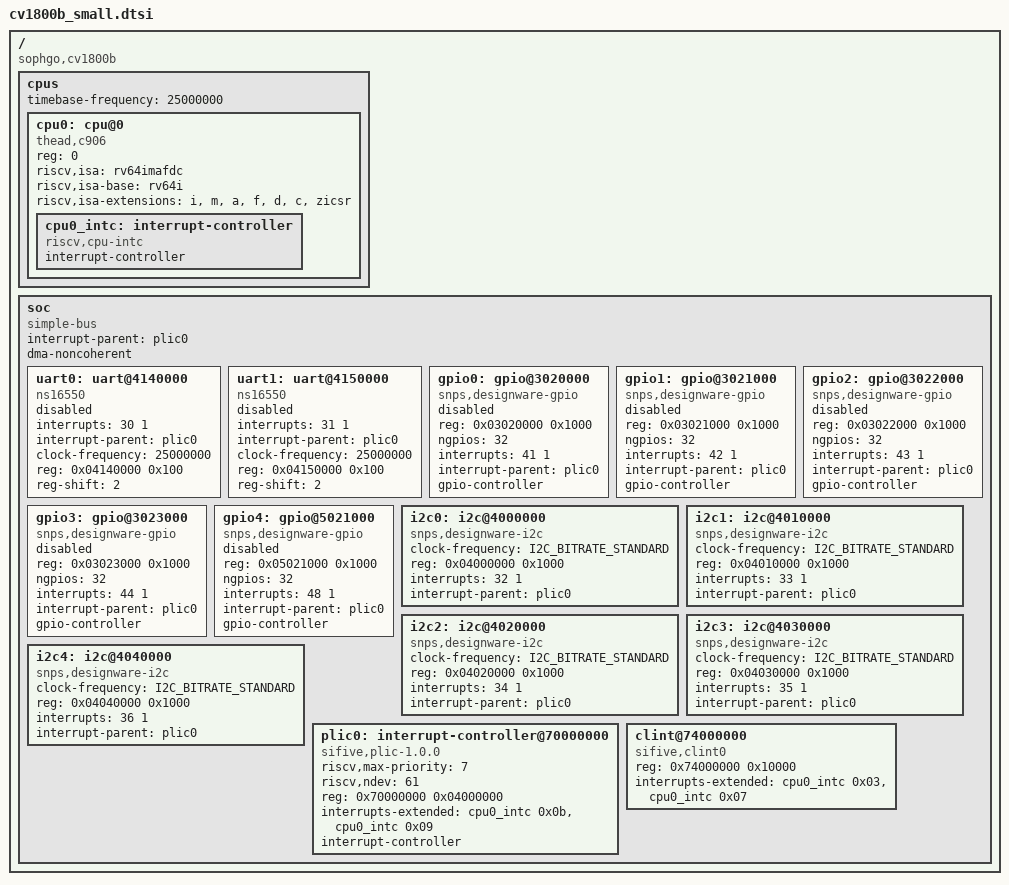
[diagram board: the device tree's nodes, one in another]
// SPDX-License-Identifier: (GPL-2.0 OR MIT)
/*
 * Copyright (C) 2024 Junhui Liu <liujh2818@outlook.com>
 */

#include <zephyr/dt-bindings/i2c/i2c.h>

/ {
	compatible = "sophgo,cv1800b";
	#address-cells = <1>;
	#size-cells = <1>;

	cpus: cpus {
		#address-cells = <1>;
		#size-cells = <0>;
		timebase-frequency = <25000000>;

		cpu0: cpu@0 {
			compatible = "thead,c906", "riscv";
			device_type = "cpu";
			reg = <0>;
			riscv,isa = "rv64imafdc";
			riscv,isa-base = "rv64i";
			riscv,isa-extensions = "i", "m", "a", "f", "d", "c", "zicsr";

			cpu0_intc: interrupt-controller {
				compatible = "riscv,cpu-intc";
				interrupt-controller;
				#interrupt-cells = <1>;
			};
		};
	};

	soc {
		compatible = "simple-bus";
		interrupt-parent = <&plic0>;
		#address-cells = <1>;
		#size-cells = <1>;
		dma-noncoherent;
		ranges;

		uart0: uart@4140000 {
			interrupts = < 30 1 >;
			interrupt-parent = < &plic0 >;
			clock-frequency = < 25000000 >;
			reg = < 0x04140000 0x100 >;
			compatible = "ns16550";
			reg-shift = < 2 >;
			status = "disabled";
		};

		uart1: uart@4150000 {
			interrupts = < 31 1 >;
			interrupt-parent = < &plic0 >;
			clock-frequency = < 25000000 >;
			reg = < 0x04150000 0x100 >;
			compatible = "ns16550";
			reg-shift = < 2 >;
			status = "disabled";
		};

		gpio0: gpio@3020000 {						/* porta */
			#address-cells = <1>;
			#size-cells = <0>;
			compatible = "snps,designware-gpio";
			reg = <0x03020000 0x1000>;
			ngpios = <32>;
			interrupts = < 41 1 >;
			interrupt-parent = < &plic0 >;

			gpio-controller;
			#gpio-cells = <2>;
			status = "disabled";
		};

		gpio1: gpio@3021000 {						/* portb */
			compatible = "snps,designware-gpio";
			reg = <0x03021000 0x1000>;
			ngpios = <32>;
			interrupts = < 42 1 >;
			interrupt-parent = < &plic0 >;

			gpio-controller;
			#gpio-cells = <2>;
			status = "disabled";
		};

		gpio2: gpio@3022000 {						/* portc */
			compatible = "snps,designware-gpio";
			reg = <0x03022000 0x1000>;
			ngpios = <32>;
			interrupts = < 43 1 >;
			interrupt-parent = < &plic0 >;

			gpio-controller;
			#gpio-cells = <2>;
			status = "disabled";
		};

		gpio3: gpio@3023000 {						/* portd */
			compatible = "snps,designware-gpio";
			reg = <0x03023000 0x1000>;
			ngpios = <32>;
			interrupts = < 44 1 >;
			interrupt-parent = < &plic0 >;

			gpio-controller;
			#gpio-cells = <2>;
			status = "disabled";
		};

		gpio4: gpio@5021000 {						/* porte */
			compatible = "snps,designware-gpio";
			reg = <0x05021000 0x1000>;
			ngpios = <32>;
			interrupts = < 48 1 >;
			interrupt-parent = < &plic0 >;

			gpio-controller;
			#gpio-cells = <2>;
			status = "disabled";
		};

		i2c0: i2c@4000000 {
			compatible = "snps,designware-i2c";
			clock-frequency = <I2C_BITRATE_STANDARD>;
			#address-cells = <1>;
			#size-cells = <0>;
			reg = <0x04000000 0x1000>;
			interrupts = <32 1>;
			interrupt-parent = <&plic0>;

			status = "okay";
		};
	
		i2c1: i2c@4010000 {
			compatible = "snps,designware-i2c";
			clock-frequency = <I2C_BITRATE_STANDARD>;
			#address-cells = <1>;
			#size-cells = <0>;
			reg = <0x04010000 0x1000>;
			interrupts = <33 1>;
			interrupt-parent = <&plic0>;

			status = "okay";
		};

		i2c2: i2c@4020000 {
			compatible = "snps,designware-i2c";
			clock-frequency = <I2C_BITRATE_STANDARD>;
			#address-cells = <1>;
			#size-cells = <0>;
			reg = <0x04020000 0x1000>;
			interrupts = <34 1>;
			interrupt-parent = <&plic0>;

			status = "okay";
		};

		i2c3: i2c@4030000 {
			compatible = "snps,designware-i2c";
			clock-frequency = <I2C_BITRATE_STANDARD>;
			#address-cells = <1>;
			#size-cells = <0>;
			reg = <0x04030000 0x1000>;
			interrupts = <35 1>;
			interrupt-parent = <&plic0>;

			status = "okay";
		};

		i2c4: i2c@4040000 {
			compatible = "snps,designware-i2c";
			clock-frequency = <I2C_BITRATE_STANDARD>;
			#address-cells = <1>;
			#size-cells = <0>;
			reg = <0x04040000 0x1000>;
			interrupts = <36 1>;
			interrupt-parent = <&plic0>;

			status = "okay";
		};

		plic0: interrupt-controller@70000000 {
			riscv,max-priority = <7>;
			riscv,ndev = < 61 >;
			reg = <0x70000000 0x04000000>;
			interrupts-extended = <&cpu0_intc 0x0b &cpu0_intc 0x09>;
			interrupt-controller;
			compatible = "sifive,plic-1.0.0";
			#address-cells = < 0x00 >;
			#interrupt-cells = < 0x02 >;
		};

		clint@74000000 {
			compatible = "sifive,clint0";
			reg = <0x74000000 0x10000>;
			interrupts-extended = <&cpu0_intc 0x03 &cpu0_intc 0x07>;
		};
	};
};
